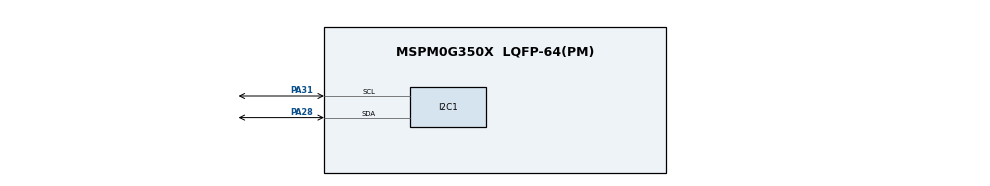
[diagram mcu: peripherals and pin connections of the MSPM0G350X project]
/**
 * @cliArgs --device "MSPM0G350X" --package "LQFP-64(PM)" --part "Default" --product "mspm0_sdk@2.01.00.03"
 * @versions {"tool":"1.20.0+3587"}
 */

/**
 * Import the modules used in this configuration.
 */
const GPIO   = scripting.addModule("/ti/driverlib/GPIO", {}, false);
const GPIO1  = GPIO.addInstance();
const GPIO2  = GPIO.addInstance();
const I2C    = scripting.addModule("/ti/driverlib/I2C", {}, false);
const I2C1   = I2C.addInstance();
const SYSCTL = scripting.addModule("/ti/driverlib/SYSCTL");
const TIMER  = scripting.addModule("/ti/driverlib/TIMER", {}, false);
const TIMER1 = TIMER.addInstance();

/**
 * Write custom configuration values to the imported modules.
 */
GPIO1.$name                               = "GPIO_led";
GPIO1.associatedPins.create(2);
GPIO1.associatedPins[0].$name             = "PIN_0";
GPIO1.associatedPins[0].launchPadShortcut = "LED1En";
GPIO1.associatedPins[0].initialValue      = "SET";
GPIO1.associatedPins[1].$name             = "PIN_22";
GPIO1.associatedPins[1].launchPadShortcut = "LED2BlueEn";

const Board = scripting.addModule("/ti/driverlib/Board", {}, false);

GPIO2.$name                               = "GPIO_key";
GPIO2.associatedPins.create(2);
GPIO2.associatedPins[0].launchPadShortcut = "Button2En";
GPIO2.associatedPins[0].$name             = "PIN_18";
GPIO2.associatedPins[0].internalResistor  = "PULL_DOWN";
GPIO2.associatedPins[1].launchPadShortcut = "Button3En";
GPIO2.associatedPins[1].$name             = "PIN_21";

I2C1.$name                           = "I2C_0";
I2C1.basicEnableController           = true;
I2C1.basicControllerStandardBusSpeed = "Fast";
I2C1.peripheral.$assign              = "I2C0";
I2C1.peripheral.sdaPin.$assign       = "PA28";
I2C1.peripheral.sclPin.$assign       = "PA31";
I2C1.sdaPinConfig.$name              = "ti_driverlib_gpio_GPIOPinGeneric0";
I2C1.sclPinConfig.$name              = "ti_driverlib_gpio_GPIOPinGeneric1";

SYSCTL.forceDefaultClkConfig = true;

TIMER1.$name              = "TIMER_0";
TIMER1.timerClkDiv        = 5;
TIMER1.timerClkPrescale   = 256;
TIMER1.interrupts         = ["ZERO"];
TIMER1.interruptPriority  = "3";
TIMER1.timerMode          = "PERIODIC";
TIMER1.timerPeriod        = "1 s";
TIMER1.peripheral.$assign = "TIMG0";

/**
 * Pinmux solution for unlocked pins/peripherals. This ensures that minor changes to the automatic solver in a future
 * version of the tool will not impact the pinmux you originally saw.  These lines can be completely deleted in order to
 * re-solve from scratch.
 */
GPIO1.associatedPins[0].pin.$suggestSolution = "PA0";
GPIO1.associatedPins[1].pin.$suggestSolution = "PB22";
Board.peripheral.$suggestSolution            = "DEBUGSS";
Board.peripheral.swclkPin.$suggestSolution   = "PA20";
Board.peripheral.swdioPin.$suggestSolution   = "PA19";
GPIO2.associatedPins[0].pin.$suggestSolution = "PA18";
GPIO2.associatedPins[1].pin.$suggestSolution = "PB21";
SYSCTL.peripheral.$suggestSolution           = "SYSCTL";
